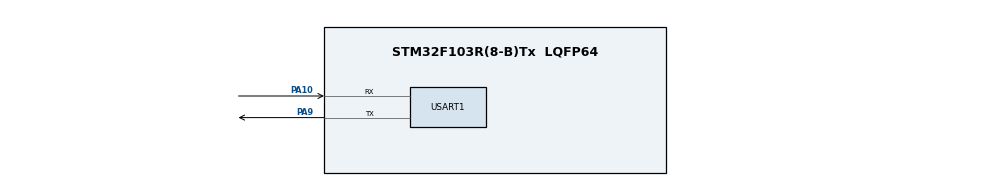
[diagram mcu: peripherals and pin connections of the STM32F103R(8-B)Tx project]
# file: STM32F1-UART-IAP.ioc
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Mcu.Family=STM32F1
Mcu.Name=STM32F103R(8-B)Tx
Mcu.Package=LQFP64
NVIC.PriorityGroup=NVIC_PRIORITYGROUP_4
PA10.Mode=Asynchronous
PA10.Signal=USART1_RX
PA13.Mode=Serial_Wire
PA13.Signal=SYS_JTMS-SWDIO
PA14.Mode=Serial_Wire
PA14.Signal=SYS_JTCK-SWCLK
PA9.Mode=Asynchronous
PA9.Signal=USART1_TX
PD0-OSC_IN.Mode=HSE-External-Oscillator
PD0-OSC_IN.Signal=RCC_OSC_IN
PD1-OSC_OUT.Mode=HSE-External-Oscillator
PD1-OSC_OUT.Signal=RCC_OSC_OUT
ProjectManager.HeapSize=0x200
ProjectManager.StackSize=0x400
ProjectManager.TargetToolchain=STM32CubeIDE
RCC.APB1Freq_Value=8000000
RCC.APB2Freq_Value=8000000
TIM2.Period=40000 - 1
TIM2.Prescaler=100
USART1.VirtualMode=VM_ASYNC
VP_TIM2_VS_ClockSourceINT.Mode=Internal
board=custom

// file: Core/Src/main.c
/* USER CODE BEGIN Header */
/**
  ******************************************************************************
  * @file           : main.c
  * @brief          : Main program body
  ******************************************************************************
  * @attention
  *
  * Copyright (c) 2024 STMicroelectronics.
  * All rights reserved.
  *
  * This software is licensed under terms that can be found in the LICENSE file
  * in the root directory of this software component.
  * If no LICENSE file comes with this software, it is provided AS-IS.
  *
  ******************************************************************************
  */
/* USER CODE END Header */
#include "main.h"
#include "tim.h"
#include "usart.h"
#include "gpio.h"

/* USER CODE BEGIN Includes */
#include <stdio.h>
#include <string.h>
#include "flash_if.h"
#include "menu.h"
/* USER CODE END Includes */

/* USER CODE BEGIN PV */
UART_HandleTypeDef UartHandle;
uint8_t timerTick;
uint8_t rxData;
/* USER CODE END PV */

void SystemClock_Config(void);

/* USER CODE BEGIN 0 */
#ifdef __GNUC__
#define PUTCHAR_PROTOTYPE int __io_putchar(int ch)
#else
#define PUTCHAR_PROTOTYPE int fputc(int ch, FILE *f)
#endif

PUTCHAR_PROTOTYPE
{
  HAL_UART_Transmit(&huart1, (uint8_t *)&ch, 1, HAL_MAX_DELAY);
  return ch;
}
/* USER CODE END 0 */

int main(void)
{

  /* MCU Configuration--------------------------------------------------------*/

  /* Reset of all peripherals, Initializes the Flash interface and the Systick. */
  HAL_Init();

  /* Configure the system clock */
  SystemClock_Config();

  /* Initialize all configured peripherals */
  MX_GPIO_Init();
  MX_USART1_UART_Init();
  MX_TIM2_Init();
  /* USER CODE BEGIN 2 */
  HAL_TIM_Base_Start_IT(&htim2);
  memcpy(&UartHandle, &huart1, sizeof(UART_HandleTypeDef));
  /* USER CODE END 2 */

  /* Infinite loop */
  while (1)
  {

    /* USER CODE BEGIN 3 */
	  if(HAL_UART_Receive(&huart1, &rxData, 1, 40) == HAL_OK) {
		  FLASH_If_Init();
		  Main_Menu();
	  }
	  else {
		  HAL_UART_Transmit(&huart1, (uint8_t*)".", 1, 1);
	  }

	  if(timerTick >= 30) {
		if (((*(__IO uint32_t*)APPLICATION_ADDRESS) & 0x2FFE0000 ) == 0x20000000) {
		  uint32_t goAddress = *((volatile uint32_t*) (APPLICATION_ADDRESS + 4));
		  void (*_jump_to_app)(void) = (void *)goAddress;
		  _jump_to_app();
		}
	  }
  }
  /* USER CODE END 3 */
}

void SystemClock_Config(void)
{
  RCC_OscInitTypeDef RCC_OscInitStruct = {0};
  RCC_ClkInitTypeDef RCC_ClkInitStruct = {0};

  /** Initializes the RCC Oscillators according to the specified parameters
  * in the RCC_OscInitTypeDef structure.
  */
  RCC_OscInitStruct.OscillatorType = RCC_OSCILLATORTYPE_HSI;
  RCC_OscInitStruct.HSIState = RCC_HSI_ON;
  RCC_OscInitStruct.HSICalibrationValue = RCC_HSICALIBRATION_DEFAULT;
  RCC_OscInitStruct.PLL.PLLState = RCC_PLL_NONE;
  if (HAL_RCC_OscConfig(&RCC_OscInitStruct) != HAL_OK)
  {
    Error_Handler();
  }

  /** Initializes the CPU, AHB and APB buses clocks
  */
  RCC_ClkInitStruct.ClockType = RCC_CLOCKTYPE_HCLK|RCC_CLOCKTYPE_SYSCLK
                              |RCC_CLOCKTYPE_PCLK1|RCC_CLOCKTYPE_PCLK2;
  RCC_ClkInitStruct.SYSCLKSource = RCC_SYSCLKSOURCE_HSI;
  RCC_ClkInitStruct.AHBCLKDivider = RCC_SYSCLK_DIV1;
  RCC_ClkInitStruct.APB1CLKDivider = RCC_HCLK_DIV1;
  RCC_ClkInitStruct.APB2CLKDivider = RCC_HCLK_DIV1;

  if (HAL_RCC_ClockConfig(&RCC_ClkInitStruct, FLASH_LATENCY_0) != HAL_OK)
  {
    Error_Handler();
  }
}

void Error_Handler(void)
{
  __disable_irq();
  while (1)
  {
  }
}
